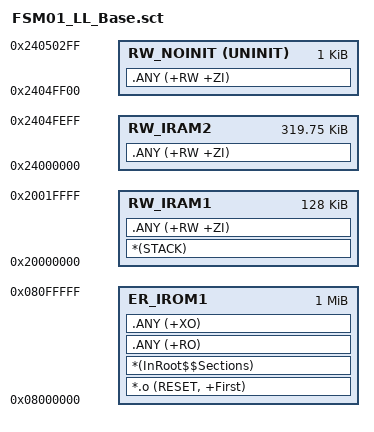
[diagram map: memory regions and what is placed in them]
; *************************************************************
; *** Scatter-Loading Description File generated by uVision ***
; *************************************************************

LR_IROM1 0x08000000 0x00100000  {    ; load region size_region
  ER_IROM1 0x08000000 0x00100000  {  ; load address = execution address
   *.o (RESET, +First)
   *(InRoot$$Sections)
   .ANY (+RO)
   .ANY (+XO)
  }
  
	/*2. */
  RW_IRAM1 0x20000000 0x00020000  {  ; RW data
	*(STACK)         ; 常见 startup 段名
	.ANY (+RW +ZI)
  }
  /*3. AXI SRAM 主区要避开末尾 0x100 */
  RW_IRAM2 0x24000000 0x0004FF00  {
  ;*(backup_buffer_section)
  ;*(stl_cpu_tm12_section)
  ;*(stl_ram_test_section)      ; <--- RAM测试专用段
  .ANY (+RW +ZI)
  }

  RW_NOINIT 0x2404FF00 UNINIT 0x00000400 {
	;*(noinit_section)
	;*(inj_noinit_bss)
	.ANY (+RW +ZI)
  } 
};
